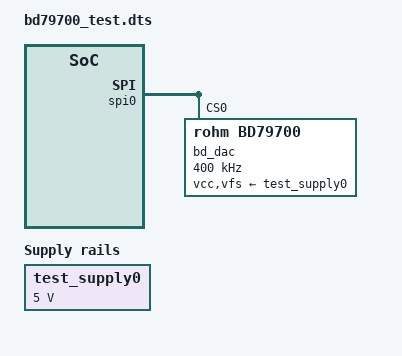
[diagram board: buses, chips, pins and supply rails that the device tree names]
/dts-v1/;
/plugin/;

#include <dt-bindings/pinctrl/omap.h>
#include <dt-bindings/pinctrl/am33xx.h>

/* SPI1 */
/* D1 Output and D0 Input */
/ {
    compatible = "ti,beaglebone", "ti,beaglebone-black";

    /* identification */
    /* part-number = "spi1mux"; */
   part-number = "spi1pinmux";

    fragment@0 {
        target = <&am33xx_pinmux>;
        __overlay__ {
            spi1_pins_s0: spi1_pins_s0 {
			/* pinctrl-single,pins = <0x150 0x28 0x00 0x154 0x28 0x00 0x158 0x08 0x00 0x15c 0x08 0x00>; */
			pinctrl-single,pins = <
				AM33XX_PADCONF(AM335X_PIN_SPI0_CS0, PIN_INPUT_PULLUP, MUX_MODE0)
				AM33XX_PADCONF(AM335X_PIN_SPI0_D0, PIN_INPUT_PULLUP, MUX_MODE0)
				AM33XX_PADCONF(AM335X_PIN_SPI0_D1, PIN_OUTPUT_PULLUP, MUX_MODE0)
				AM33XX_PADCONF(AM335X_PIN_SPI0_SCLK, PIN_INPUT_PULLUP, MUX_MODE0)>;

				/* <0x150 0x30 0x00 0x154 0x30 0x00 0x158 0x10 0x00 0x15c 0x10 0x00>; */

//                        pinctrl-single,pins = <
				/* These were all MODE3 - which is this value + 3 (Eg, 0x33 and 0x13) */
//                                0x190 0x33      /* mcasp0_aclkx.spi1_sclk, INPUT_PULLUP | MODE0 */
//                                0x194 0x33      /* mcasp0_fsx.spi1_d0, INPUT_PULLUP | MODE0 */
//                                0x198 0x13      /* mcasp0_axr0.spi1_d1, OUTPUT_PULLUP | MODE0 */
//                                0x19c 0x13      /* mcasp0_ahclkr.spi1_cs0, OUTPUT_PULLUP | MODE0 */
//                >;
            };
        };
    };

    fragment@1 {
        target-path = "/";
        __overlay__ {
		test_supply0: test_reg0 {
			compatible = "regulator-fixed";
			regulator-name = "test-reg0";
			regulator-min-microvolt = <5000000>;
			regulator-max-microvolt = <5000000>;
		};
        };

    };

    fragment@2 {
        target = <&spi0>;
        __overlay__ {

             #address-cells = <1>;
             #size-cells = <0>;
             status = "okay";
             pinctrl-names = "default";
             pinctrl-0 = <&spi1_pins_s0>;

		bd_dac: bd_dac@0 { /* the "test" defined as child of the i2c1 bus */
			compatible = "rohm,bd79700";
			reg = <0>;
			/* spi-max-frequency = <4300000>; */
			spi-max-frequency = <400000>;
			vcc-supply = <&test_supply0>;
			vfs-supply = <&test_supply0>;
		};
	};
    };
};
